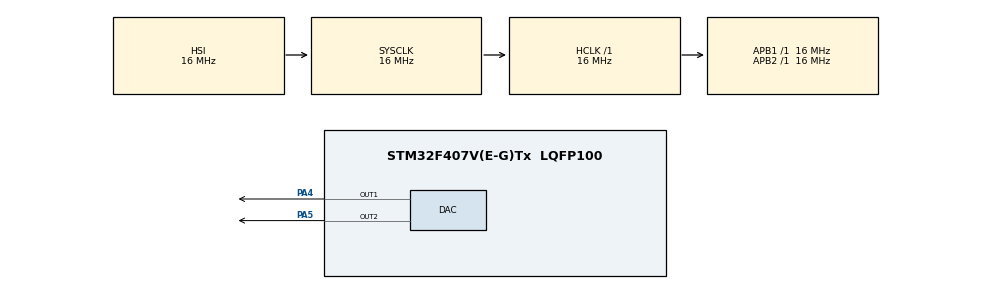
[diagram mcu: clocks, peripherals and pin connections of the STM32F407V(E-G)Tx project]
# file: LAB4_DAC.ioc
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DAC.DAC_Trigger=DAC_TRIGGER_T6_TRGO
Dma.DAC1.0.Direction=DMA_MEMORY_TO_PERIPH
Dma.DAC1.0.FIFOMode=DMA_FIFOMODE_DISABLE
Dma.DAC1.0.Instance=DMA1_Stream5
Dma.DAC1.0.MemDataAlignment=DMA_MDATAALIGN_HALFWORD
Dma.DAC1.0.MemInc=DMA_MINC_ENABLE
Dma.DAC1.0.Mode=DMA_CIRCULAR
Dma.DAC1.0.PeriphDataAlignment=DMA_PDATAALIGN_HALFWORD
Dma.DAC1.0.PeriphInc=DMA_PINC_DISABLE
Dma.DAC1.0.Priority=DMA_PRIORITY_LOW
Dma.DAC2.1.Direction=DMA_MEMORY_TO_PERIPH
Dma.DAC2.1.FIFOMode=DMA_FIFOMODE_DISABLE
Dma.DAC2.1.Instance=DMA1_Stream6
Dma.DAC2.1.MemDataAlignment=DMA_MDATAALIGN_HALFWORD
Dma.DAC2.1.MemInc=DMA_MINC_ENABLE
Dma.DAC2.1.Mode=DMA_CIRCULAR
Dma.DAC2.1.PeriphDataAlignment=DMA_PDATAALIGN_HALFWORD
Dma.DAC2.1.PeriphInc=DMA_PINC_DISABLE
Dma.DAC2.1.Priority=DMA_PRIORITY_LOW
Dma.Request0=DAC1
Dma.Request1=DAC2
Mcu.Family=STM32F4
Mcu.Name=STM32F407V(E-G)Tx
Mcu.Package=LQFP100
NVIC.DMA1_Stream5_IRQn=true\:0\:0\:false\:false\:true\:false\:true\:true
NVIC.DMA1_Stream6_IRQn=true\:0\:0\:false\:false\:true\:false\:true\:true
NVIC.PriorityGroup=NVIC_PRIORITYGROUP_4
PA13.Mode=Serial_Wire
PA13.Signal=SYS_JTMS-SWDIO
PA14.Mode=Serial_Wire
PA14.Signal=SYS_JTCK-SWCLK
PA4.Signal=COMP_DAC1_group
PA5.Signal=COMP_DAC2_group
ProjectManager.HeapSize=0x200
ProjectManager.StackSize=0x400
ProjectManager.TargetToolchain=MDK-ARM V5.32
RCC.AHBFreq_Value=16000000
RCC.APB1Freq_Value=16000000
RCC.APB2Freq_Value=16000000
RCC.CortexFreq_Value=16000000
RCC.HSE_VALUE=25000000
RCC.HSI_VALUE=16000000
RCC.LSE_VALUE=32768
RCC.SYSCLKFreq_VALUE=16000000
RCC.VCOOutputFreq_Value=192000000
SH.COMP_DAC1_group.0=DAC_OUT1,DAC_OUT1
SH.COMP_DAC2_group.0=DAC_OUT2,DAC_OUT2
TIM6.Period=10000-1
TIM6.Prescaler=16-1
TIM6.TIM_MasterOutputTrigger=TIM_TRGO_UPDATE
VP_TIM6_VS_ClockSourceINT.Mode=Enable_Timer
board=custom

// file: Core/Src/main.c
/* USER CODE BEGIN Header */
/**
  ******************************************************************************
  * @file           : main.c
  * @brief          : Main program body
  ******************************************************************************
  * @attention
  *
  * Copyright (c) 2023 STMicroelectronics.
  * All rights reserved.
  *
  * This software is licensed under terms that can be found in the LICENSE file
  * in the root directory of this software component.
  * If no LICENSE file comes with this software, it is provided AS-IS.
  *
  ******************************************************************************
  */
/* USER CODE END Header */
#include "main.h"
#include "dac.h"
#include "dma.h"
#include "tim.h"
#include "gpio.h"

/* USER CODE BEGIN Includes */
#include <math.h>
/* USER CODE END Includes */

void SystemClock_Config(void);

int main(void)
{

  /* MCU Configuration--------------------------------------------------------*/

  /* Reset of all peripherals, Initializes the Flash interface and the Systick. */
  HAL_Init();

  /* Configure the system clock */
  SystemClock_Config();

  /* Initialize all configured peripherals */
  MX_GPIO_Init();
  MX_DMA_Init();
  MX_DAC_Init();
  MX_TIM6_Init();
  /* USER CODE BEGIN 2 */
		HAL_DAC_SetValue(&hdac, DAC_CHANNEL_1, DAC_ALIGN_12B_R, 4095 / 2);
		HAL_DAC_Start(&hdac, DAC1_CHANNEL_1);
		HAL_DAC_SetValue(&hdac, DAC_CHANNEL_2, DAC_ALIGN_12B_R, 4095);
		HAL_DAC_Start(&hdac, DAC1_CHANNEL_2);
  /* USER CODE END 2 */

  /* Infinite loop */
  /* USER CODE BEGIN WHILE */
	#define MAX_SIZE 100
	float u = 0;
	uint16_t U[2 * MAX_SIZE] = {0};
	float alfa = 0;
	uint16_t index = 0;

	for (index = 0; index <MAX_SIZE; index ++)
	{
		alfa = 360 * index / MAX_SIZE;
		u = 1 * sin (3.14 * alfa / 180);
		U[index] = u * (0x0FFF / 2 - 0x003F) + 1 * 0x0FFF / 2;
	}
//	for (index = 0; index <MAX_SIZE; index ++)
//	{
//		U[index + MAX_SIZE] = 40 * index;
//	}
//	for (index = 0; index <MAX_SIZE; index ++)
//	{
//		alfa = 360 * index / MAX_SIZE;
//		u = 1 * cos (3.14 * alfa / 180);
//		U[index + MAX_SIZE] = u * (0x0FFF / 2 - 0x003F) + 1 * 0x0FFF / 2;
//	}
	for (index = 0; index <MAX_SIZE; index ++)
	{
		if (index < (MAX_SIZE / 2))
		{
			U[index + MAX_SIZE] = 0;
		}
		else
		{
			U[index + MAX_SIZE] = 0x0FFF / 2;
		}
	}
	//index = 0;

	//HAL_DAC_Start(&hdac, DAC1_CHANNEL_1);
	HAL_DAC_Start_DMA(&hdac, DAC1_CHANNEL_1, (uint32_t *)U, 2 * MAX_SIZE, DAC_ALIGN_12B_R);

	__HAL_TIM_SET_AUTORELOAD(&htim6, 1000-1);
	HAL_TIM_Base_Start(&htim6);

  while (1)
  {
//		HAL_DAC_SetValue(&hdac, DAC_CHANNEL_1, DAC_ALIGN_12B_R, (uint32_t)U[index]);

//		index++;
//		if(index >= MAX_SIZE)
//		{
//			index = 0;
//		}
		/* u(t) = A * sin(wt); */
//		alfa += 20;
//		if (alfa > 360)
//		{
//			alfa = 0;
//		}
//		u = 1 * sin (3.14 * alfa / 180);
//		U = (u + 1) * 4095 / 2;
//
    /* USER CODE END WHILE */

  }
}

void SystemClock_Config(void)
{
  RCC_OscInitTypeDef RCC_OscInitStruct = {0};
  RCC_ClkInitTypeDef RCC_ClkInitStruct = {0};

  /** Configure the main internal regulator output voltage
  */
  __HAL_RCC_PWR_CLK_ENABLE();
  __HAL_PWR_VOLTAGESCALING_CONFIG(PWR_REGULATOR_VOLTAGE_SCALE1);

  /** Initializes the RCC Oscillators according to the specified parameters
  * in the RCC_OscInitTypeDef structure.
  */
  RCC_OscInitStruct.OscillatorType = RCC_OSCILLATORTYPE_HSI;
  RCC_OscInitStruct.HSIState = RCC_HSI_ON;
  RCC_OscInitStruct.HSICalibrationValue = RCC_HSICALIBRATION_DEFAULT;
  RCC_OscInitStruct.PLL.PLLState = RCC_PLL_NONE;
  if (HAL_RCC_OscConfig(&RCC_OscInitStruct) != HAL_OK)
  {
    Error_Handler();
  }

  /** Initializes the CPU, AHB and APB buses clocks
  */
  RCC_ClkInitStruct.ClockType = RCC_CLOCKTYPE_HCLK|RCC_CLOCKTYPE_SYSCLK
                              |RCC_CLOCKTYPE_PCLK1|RCC_CLOCKTYPE_PCLK2;
  RCC_ClkInitStruct.SYSCLKSource = RCC_SYSCLKSOURCE_HSI;
  RCC_ClkInitStruct.AHBCLKDivider = RCC_SYSCLK_DIV1;
  RCC_ClkInitStruct.APB1CLKDivider = RCC_HCLK_DIV1;
  RCC_ClkInitStruct.APB2CLKDivider = RCC_HCLK_DIV1;

  if (HAL_RCC_ClockConfig(&RCC_ClkInitStruct, FLASH_LATENCY_0) != HAL_OK)
  {
    Error_Handler();
  }
}

void Error_Handler(void)
{
  __disable_irq();
  while (1)
  {
  }
}
